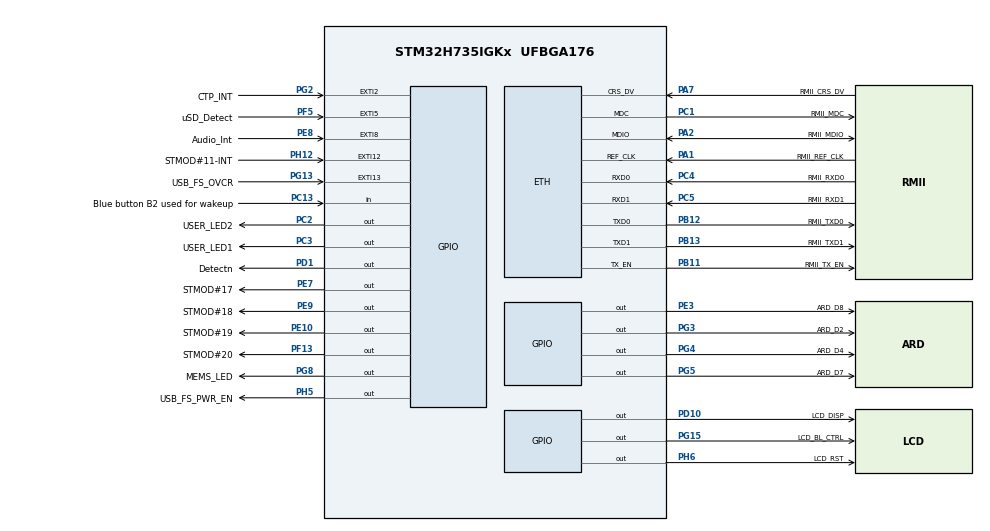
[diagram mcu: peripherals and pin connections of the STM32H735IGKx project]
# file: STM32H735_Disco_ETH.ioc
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CORTEX_M7.AccessPermission_S-Cortex_Memory_Protection_Unit_Region1_Settings_S=MPU_REGION_FULL_ACCESS
CORTEX_M7.AccessPermission_S-Cortex_Memory_Protection_Unit_Region2_Settings_S=MPU_REGION_FULL_ACCESS
CORTEX_M7.BaseAddress_S-Cortex_Memory_Protection_Unit_Region1_Settings_S=0x30000000
CORTEX_M7.BaseAddress_S-Cortex_Memory_Protection_Unit_Region2_Settings_S=0x30000000
CORTEX_M7.CPU_DCache=Enabled
CORTEX_M7.CPU_ICache=Enabled
CORTEX_M7.DisableExec_S-Cortex_Memory_Protection_Unit_Region1_Settings_S=MPU_INSTRUCTION_ACCESS_DISABLE
CORTEX_M7.DisableExec_S-Cortex_Memory_Protection_Unit_Region2_Settings_S=MPU_INSTRUCTION_ACCESS_DISABLE
CORTEX_M7.Enable_S-Cortex_Memory_Protection_Unit_Region1_Settings_S=MPU_REGION_ENABLE
CORTEX_M7.Enable_S-Cortex_Memory_Protection_Unit_Region2_Settings_S=MPU_REGION_ENABLE
CORTEX_M7.IsBufferable_S-Cortex_Memory_Protection_Unit_Region2_Settings_S=MPU_ACCESS_BUFFERABLE
CORTEX_M7.IsShareable_S-Cortex_Memory_Protection_Unit_Region2_Settings_S=MPU_ACCESS_SHAREABLE
CORTEX_M7.Size_S-Cortex_Memory_Protection_Unit_Region1_Settings_S=MPU_REGION_SIZE_32KB
CORTEX_M7.Size_S-Cortex_Memory_Protection_Unit_Region2_Settings_S=MPU_REGION_SIZE_512B
CORTEX_M7.TypeExtField_S-Cortex_Memory_Protection_Unit_Region1_Settings_S=MPU_TEX_LEVEL1
CORTEX_M7.default_mode_Activation=1
ETH.MediaInterface=HAL_ETH_RMII_MODE
ETH.RxBuffAddress=0x30000200
ETH.RxBuffLen=1536
ETH.TxDescAddress=0x30000100
FREERTOS.Tasks01=defaultTask,24,512,StartDefaultTask,Default,NULL,Dynamic,NULL,NULL
FREERTOS.configCHECK_FOR_STACK_OVERFLOW=1
FREERTOS.configMINIMAL_STACK_SIZE=512
FREERTOS.configTOTAL_HEAP_SIZE=30*1024
FREERTOS.configUSE_NEWLIB_REENTRANT=1
LWIP.BSP.number=1
LWIP.IP_ADDRESS=192.168.001.010
LWIP.LWIP_DHCP=0
LWIP.LWIP_RAM_HEAP_POINTER=0x30000200
LWIP.MEM_SIZE=32232
LWIP.NETMASK_ADDRESS=255.255.255.000
LWIP.TCP_MSS=1460
LWIP.TCP_SND_BUF=5840
LWIP.TCP_SND_QUEUELEN=16
LWIP.Version=v2.1.2_Cube
LWIP0.BSP.STBoard=false
LWIP0.BSP.api=BSP_COMPONENT_DRIVER
LWIP0.BSP.component=LAN8742
LWIP0.BSP.i2caddr=0
LWIP0.BSP.instance=LAN8742
LWIP0.BSP.name=Driver_PHY
LWIP0.BSP.semaphore=S_LAN8742
LWIP0.BSP.solution=LAN8742
Mcu.Family=STM32H7
Mcu.Name=STM32H735IGKx
Mcu.Package=UFBGA176
NVIC.ETH_IRQn=true\:5\:0\:false\:false\:true\:true\:true\:true\:true
NVIC.PriorityGroup=NVIC_PRIORITYGROUP_4
NVIC.TIM6_DAC_IRQn=true\:15\:0\:false\:false\:true\:false\:false\:true\:true
NVIC.TimeBase=TIM6_DAC_IRQn
NVIC.TimeBaseIP=TIM6
PA0.GPIO_Label=ARD_D3
PA0.Signal=S_TIM5_CH1
PA0_C.GPIO_Label=ARD_A2
PA0_C.Signal=ADCx_INP0
PA1.GPIO_Label=RMII_REF_CLK
PA1.GPIO_Speed=GPIO_SPEED_FREQ_VERY_HIGH
PA1.Mode=RMII
PA1.Signal=ETH_REF_CLK
PA10.GPIO_Label=USB_FS_ID
PA10.Signal=USB_OTG_HS_ID
PA11.GPIO_Label=USB_FS_DM
PA11.Signal=USB_OTG_HS_DM
PA12.GPIO_Label=USB_FS_DP
PA12.Signal=USB_OTG_HS_DP
PA13(JTMS/SWDIO).GPIO_Label=JTMS
PA13(JTMS/SWDIO).Signal=DEBUG_JTMS-SWDIO
PA14(JTCK/SWCLK).GPIO_Label=JTCK
PA14(JTCK/SWCLK).Signal=DEBUG_JTCK-SWCLK
PA15(JTDI).GPIO_Label=JTDI
PA15(JTDI).Signal=DEBUG_JTDI
PA1_C.GPIO_Label=ARD_A3
PA1_C.Signal=ADCx_INP1
PA2.GPIO_Label=RMII_MDIO
PA2.GPIO_Speed=GPIO_SPEED_FREQ_VERY_HIGH
PA2.Mode=RMII
PA2.Signal=ETH_MDIO
PA3.GPIO_Label=LCD_B5
PA3.GPIO_Speed=GPIO_SPEED_FREQ_LOW
PA3.Signal=LTDC_B5
PA4.GPIO_Label=LCD_VSYNC
PA4.GPIO_Speed=GPIO_SPEED_FREQ_LOW
PA4.Signal=LTDC_VSYNC
PA5.GPIO_Label=DAC1_OUT2
PA5.Signal=COMP_DAC12_group
PA6.GPIO_Label=LCD_G2
PA6.GPIO_Speed=GPIO_SPEED_FREQ_LOW
PA6.Signal=LTDC_G2
PA7.GPIO_Label=RMII_CRS_DV
PA7.GPIO_Speed=GPIO_SPEED_FREQ_VERY_HIGH
PA7.Mode=RMII
PA7.Signal=ETH_CRS_DV
PA8.GPIO_Label=LCD_B3
PA8.GPIO_Speed=GPIO_SPEED_FREQ_LOW
PA8.Signal=LTDC_B3
PA9.GPIO_Label=USB_FS_VBUS
PA9.Signal=USB_OTG_HS_VBUS
PB0.GPIO_Label=LCD_G1
PB0.GPIO_Speed=GPIO_SPEED_FREQ_LOW
PB0.Signal=LTDC_G1
PB1.GPIO_Label=LCD_G0
PB1.GPIO_Speed=GPIO_SPEED_FREQ_LOW
PB1.Signal=LTDC_G0
PB10.GPIO_Label=RMII_RX_ER
PB10.Signal=ETH_RX_ER
PB11.GPIO_Label=RMII_TX_EN
PB11.GPIO_Speed=GPIO_SPEED_FREQ_VERY_HIGH
PB11.Mode=RMII
PB11.Signal=ETH_TX_EN
PB12.GPIO_Label=RMII_TXD0
PB12.GPIO_Speed=GPIO_SPEED_FREQ_VERY_HIGH
PB12.Mode=RMII
PB12.Signal=ETH_TXD0
PB13.GPIO_Label=RMII_TXD1
PB13.GPIO_Speed=GPIO_SPEED_FREQ_VERY_HIGH
PB13.Mode=RMII
PB13.Signal=ETH_TXD1
PB14.GPIO_Label=ARD_D1
PB14.GPIO_PuPd=GPIO_NOPULL
PB14.Signal=USART1_TX
PB15.GPIO_Label=ARD_D0
PB15.GPIO_PuPd=GPIO_NOPULL
PB15.Signal=USART1_RX
PB2.GPIO_Label=OCSPI1_DQS
PB2.Signal=OCTOSPIM_P1_DQS
PB3(JTDO/TRACESWO).GPIO_Label=JTDO
PB3(JTDO/TRACESWO).Signal=DEBUG_JTDO-SWO
PB4(NJTRST).GPIO_Label=NJTRST
PB4(NJTRST).Signal=DEBUG_JTRST
PB5.GPIO_Label=FDCAN2_RX
PB5.Signal=FDCAN2_RX
PB6.GPIO_Label=FDCAN2_TX
PB6.Signal=FDCAN2_TX
PB7.GPIO_Label=ARD_D9
PB7.Signal=S_TIM4_CH2
PB8.GPIO_Label=LCD_B6
PB8.GPIO_Speed=GPIO_SPEED_FREQ_LOW
PB8.Signal=LTDC_B6
PB9.GPIO_Label=LCD_B7
PB9.GPIO_Speed=GPIO_SPEED_FREQ_LOW
PB9.Signal=LTDC_B7
PC0.GPIO_Label=ARD_A0
PC0.Signal=ADCx_INP10
PC1.GPIO_Label=RMII_MDC
PC1.GPIO_Speed=GPIO_SPEED_FREQ_VERY_HIGH
PC1.Mode=RMII
PC1.Signal=ETH_MDC
PC10.GPIO_Label=SDIO1_D2
PC10.Signal=SDMMC1_D2
PC11.GPIO_Label=SDIO1_D3
PC11.Signal=SDMMC1_D3
PC12.GPIO_Label=SDIO1_CK
PC12.Signal=SDMMC1_CK
PC13.GPIO_Label=Blue button B2 used for wakeup
PC13.Signal=GPIO_Input
PC2.GPIO_Label=USER_LED2
PC2.Signal=GPIO_Output
PC2_C.GPIO_Label=ARD_A4
PC2_C.Signal=ADC3_INP0
PC3.GPIO_Label=USER_LED1
PC3.Signal=GPIO_Output
PC3_C.GPIO_Label=ARD_A5
PC3_C.Signal=ADC3_INP1
PC4.GPIO_Label=RMII_RXD0
PC4.GPIO_Speed=GPIO_SPEED_FREQ_VERY_HIGH
PC4.Mode=RMII
PC4.Signal=ETH_RXD0
PC5.GPIO_Label=RMII_RXD1
PC5.GPIO_Speed=GPIO_SPEED_FREQ_VERY_HIGH
PC5.Mode=RMII
PC5.Signal=ETH_RXD1
PC6.GPIO_Label=LCD_HSYNC
PC6.GPIO_Speed=GPIO_SPEED_FREQ_LOW
PC6.Signal=LTDC_HSYNC
PC7.GPIO_Label=LCD_G6
PC7.GPIO_Speed=GPIO_SPEED_FREQ_LOW
PC7.Signal=LTDC_G6
PC8.GPIO_Label=SDIO1_D0
PC8.Signal=SDMMC1_D0
PC9.GPIO_Label=SDIO1_D1
PC9.Signal=SDMMC1_D1
PD0.GPIO_Label=LCD_B1
PD0.GPIO_Speed=GPIO_SPEED_FREQ_LOW
PD0.Signal=LTDC_B1
PD1.GPIO_Label=Detectn
PD1.GPIO_PuPd=GPIO_NOPULL
PD1.Signal=GPIO_Output
PD10.GPIO_Label=LCD_DISP
PD10.GPIO_Speed=GPIO_SPEED_FREQ_LOW
PD10.Signal=GPIO_Output
PD11.GPIO_Label=OCSPI1_IO0
PD11.Signal=OCTOSPIM_P1_IO0
PD12.GPIO_Label=OCSPI1_IO1
PD12.Signal=OCTOSPIM_P1_IO1
PD13.GPIO_Label=OCSPI1_IO3
PD13.Signal=OCTOSPIM_P1_IO3
PD14.GPIO_Label=STMOD\#14-PWM
PD14.Signal=S_TIM4_CH3
PD15.GPIO_Label=ARD_D6
PD15.Signal=S_TIM4_CH4
PD2.GPIO_Label=SDIO1_CMD
PD2.Signal=SDMMC1_CMD
PD3.GPIO_Label=LCD_G7
PD3.GPIO_Speed=GPIO_SPEED_FREQ_LOW
PD3.Signal=LTDC_G7
PD4.GPIO_Label=OCSPI1_IO4
PD4.Signal=OCTOSPIM_P1_IO4
PD5.GPIO_Label=OCSPI1_IO5
PD5.Signal=OCTOSPIM_P1_IO5
PD6.GPIO_Label=LCD_B2
PD6.GPIO_Speed=GPIO_SPEED_FREQ_LOW
PD6.Signal=LTDC_B2
PD7.GPIO_Label=OCSPI1_IO7
PD7.Signal=OCTOSPIM_P1_IO7
PD8.GPIO_Label=T_VCP_TX
PD8.GPIO_PuPd=GPIO_NOPULL
PD8.Signal=USART3_TX
PD9.GPIO_Label=T_VCP_RX
PD9.GPIO_PuPd=GPIO_NOPULL
PD9.Signal=USART3_RX
PE0.GPIO_Label=LCD_R0
PE0.GPIO_Speed=GPIO_SPEED_FREQ_LOW
PE0.Signal=LTDC_R0
PE1.GPIO_Label=LCD_R6
PE1.GPIO_Speed=GPIO_SPEED_FREQ_LOW
PE1.Signal=LTDC_R6
PE10.GPIO_Label=STMOD\#19
PE10.Signal=GPIO_Output
PE11.GPIO_Label=LCD_G3
PE11.GPIO_Speed=GPIO_SPEED_FREQ_LOW
PE11.Signal=LTDC_G3
PE12.GPIO_Label=LCD_B4
PE12.GPIO_Speed=GPIO_SPEED_FREQ_LOW
PE12.Signal=LTDC_B4
PE13.GPIO_Label=LCD_DE
PE13.GPIO_Speed=GPIO_SPEED_FREQ_LOW
PE13.Signal=LTDC_DE
PE14.GPIO_Label=ARD_D5
PE14.Signal=S_TIM1_CH4
PE15.GPIO_Label=LCD_R7
PE15.GPIO_Speed=GPIO_SPEED_FREQ_LOW
PE15.Signal=LTDC_R7
PE2.GPIO_Label=OCSPI1_IO2
PE2.Signal=OCTOSPIM_P1_IO2
PE3.GPIO_Label=ARD_D8
PE3.Signal=GPIO_Output
PE4.GPIO_Label=SAI4_D2
PE4.Signal=SAI4_D2
PE5.GPIO_Label=SAI4_CK2
PE5.Signal=SAI4_CK2
PE6.GPIO_Label=SAI1_SD_A
PE6.Signal=SAI1_SD_A
PE7.GPIO_Label=STMOD\#17
PE7.Signal=GPIO_Output
PE8.GPIO_Label=Audio_Int
PE8.Signal=GPXTI8
PE9.GPIO_Label=STMOD\#18
PE9.Signal=GPIO_Output
PF0.GPIO_Label=OCSPI2_IO0
PF0.Signal=OCTOSPIM_P2_IO0
PF1.GPIO_Label=OCSPI2_IO1
PF1.Signal=OCTOSPIM_P2_IO1
PF10.GPIO_Label=OCSPI1_CLK
PF10.Signal=OCTOSPIM_P1_CLK
PF11.GPIO_Label=SPI5_MOSI
PF11.Signal=SPI5_MOSI
PF12.GPIO_Label=OCSPI2_DQS
PF12.Signal=OCTOSPIM_P2_DQS
PF13.GPIO_Label=STMOD\#20
PF13.Signal=GPIO_Output
PF14.GPIO_Label=I2C4_SCL
PF14.Signal=I2C4_SCL
PF15.GPIO_Label=I2C4_SDA
PF15.Signal=I2C4_SDA
PF2.GPIO_Label=OCSPI2_IO2
PF2.Signal=OCTOSPIM_P2_IO2
PF3.GPIO_Label=OCSPI2_IO3
PF3.Signal=OCTOSPIM_P2_IO3
PF4.GPIO_Label=OCSPI2_CLK
PF4.Signal=OCTOSPIM_P2_CLK
PF5.GPIO_Label=uSD_Detect
PF5.Signal=GPXTI5
PF6.GPIO_Label=SAI1_SD_B
PF6.Signal=SAI1_SD_B
PF7.GPIO_Label=SAI1_MCLK_B
PF7.Signal=SAI1_MCLK_B
PF8.GPIO_Label=SAI1_SCK_B
PF8.Signal=SAI1_SCK_B
PF9.GPIO_Label=SAI1_FS_B
PF9.Signal=SAI1_FS_B
PG0.GPIO_Label=OCSPI2_IO4
PG0.Signal=OCTOSPIM_P2_IO4
PG1.GPIO_Label=OCSPI2_IO5
PG1.Signal=OCTOSPIM_P2_IO5
PG10.GPIO_Label=OCSPI2_IO6
PG10.Signal=OCTOSPIM_P2_IO6
PG11.GPIO_Label=OCSPI2_IO7
PG11.Signal=OCTOSPIM_P2_IO7
PG12.GPIO_Label=OCSPI2_NCS
PG12.Signal=OCTOSPIM_P2_NCS
PG13.GPIO_Label=USB_FS_OVCR
PG13.Signal=GPXTI13
PG14.GPIO_Label=LCD_B0
PG14.GPIO_Speed=GPIO_SPEED_FREQ_LOW
PG14.Signal=LTDC_B0
PG15.GPIO_Label=LCD_BL_CTRL
PG15.GPIO_Speed=GPIO_SPEED_FREQ_LOW
PG15.Signal=GPIO_Output
PG2.GPIO_Label=CTP_INT
PG2.Signal=GPXTI2
PG3.GPIO_Label=ARD_D2
PG3.Signal=GPIO_Output
PG4.GPIO_Label=ARD_D4
PG4.Signal=GPIO_Output
PG5.GPIO_Label=ARD_D7
PG5.Signal=GPIO_Output
PG6.GPIO_Label=OCSPI1_NCS
PG6.Signal=OCTOSPIM_P1_NCS
PG7.GPIO_Label=LCD_CLK
PG7.GPIO_Speed=GPIO_SPEED_FREQ_LOW
PG7.Signal=LTDC_CLK
PG8.GPIO_Label=MEMS_LED
PG8.Signal=GPIO_Output
PG9.GPIO_Label=OCSPI1_IO6
PG9.Signal=OCTOSPIM_P1_IO6
PH10.GPIO_Label=LCD_R4
PH10.GPIO_Speed=GPIO_SPEED_FREQ_LOW
PH10.Signal=LTDC_R4
PH11.GPIO_Label=LCD_R5
PH11.GPIO_Speed=GPIO_SPEED_FREQ_LOW
PH11.Signal=LTDC_R5
PH12.GPIO_Label=STMOD\#11-INT
PH12.Signal=GPXTI12
PH13.GPIO_Label=FDCAN1_TX
PH13.Signal=FDCAN1_TX
PH14.GPIO_Label=FDCAN1_RX
PH14.Signal=FDCAN1_RX
PH15.GPIO_Label=LCD_G4
PH15.GPIO_Speed=GPIO_SPEED_FREQ_LOW
PH15.Signal=LTDC_G4
PH2.GPIO_Label=ARD_A1
PH2.Signal=ADC3_INP13
PH3.GPIO_Label=LCD_R1
PH3.GPIO_Speed=GPIO_SPEED_FREQ_LOW
PH3.Signal=LTDC_R1
PH4.GPIO_Label=LCD_G5
PH4.GPIO_Speed=GPIO_SPEED_FREQ_LOW
PH4.Signal=LTDC_G5
PH5.GPIO_Label=USB_FS_PWR_EN
PH5.Signal=GPIO_Output
PH6.GPIO_Label=LCD_RST
PH6.GPIO_Speed=GPIO_SPEED_FREQ_LOW
PH6.Signal=GPIO_Output
PH7.GPIO_Label=SPI5_MISO
PH7.Signal=SPI5_MISO
PH8.GPIO_Label=LCD_R2
PH8.GPIO_Speed=GPIO_SPEED_FREQ_LOW
PH8.Signal=LTDC_R2
PH9.GPIO_Label=LCD_R3
PH9.GPIO_Speed=GPIO_SPEED_FREQ_LOW
PH9.Signal=LTDC_R3
ProjectManager.HeapSize=0x200
ProjectManager.StackSize=0x400
ProjectManager.TargetToolchain=STM32CubeIDE
RCC.ADCFreq_Value=204800000
RCC.APB1Freq_Value=125000000
RCC.APB2Freq_Value=125000000
RCC.APB3Freq_Value=125000000
RCC.APB4Freq_Value=125000000
RCC.CortexFreq_Value=500000000
RCC.D1PPRE=RCC_APB3_DIV2
RCC.D2PPRE1=RCC_APB1_DIV2
RCC.D2PPRE2=RCC_APB2_DIV2
RCC.D3PPRE=RCC_APB4_DIV2
RCC.DIVM1=16
RCC.DIVM2=5
RCC.DIVN1=125
RCC.DIVN2=80
RCC.DIVP1=1
RCC.DIVP2=5
RCC.DIVQ1=4
RCC.HCLKFreq_Value=250000000
RCC.HPRE=RCC_HCLK_DIV2
RCC.PLL2FRACN=0
RCC.PLL3FRACN=0
RCC.PLLFRACN=0
RCC.SYSCLKFreq_VALUE=500000000
RCC.SYSCLKSource=RCC_SYSCLKSOURCE_PLLCLK
RCC.USBCLockSelection=RCC_USBCLKSOURCE_HSI48
RCC.USBFreq_Value=48000000
SH.ADCx_INP0.0=ADC1_INP0
SH.ADCx_INP0.1=ADC2_INP0
SH.ADCx_INP1.0=ADC2_INP1
SH.ADCx_INP1.1=ADC1_INP1
SH.ADCx_INP10.0=ADC1_INP10
SH.COMP_DAC12_group.0=DAC1_OUT2
SH.S_TIM1_CH4.0=TIM1_CH4
SH.S_TIM4_CH2.0=TIM4_CH2
SH.S_TIM4_CH3.0=TIM4_CH3
SH.S_TIM4_CH4.0=TIM4_CH4
SH.S_TIM5_CH1.0=TIM5_CH1
VP_FREERTOS_VS_CMSIS_V2.Mode=CMSIS_V2
VP_LWIP_VS_Enabled.Mode=Enabled
VP_SYS_VS_tim6.Mode=TIM6
board=STM32H735G-DK

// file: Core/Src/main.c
/* USER CODE BEGIN Header */
/**
  ******************************************************************************
  * @file           : main.c
  * @brief          : Main program body
  ******************************************************************************
  * @attention
  *
  * Copyright (c) 2022 STMicroelectronics.
  * All rights reserved.
  *
  * This software is licensed under terms that can be found in the LICENSE file
  * in the root directory of this software component.
  * If no LICENSE file comes with this software, it is provided AS-IS.
  *
  ******************************************************************************
  */
/* USER CODE END Header */
#include "main.h"
#include "cmsis_os.h"
#include "lwip.h"

/* USER CODE BEGIN Includes */
/* ETH_CODE: add lwiperf, see comment in StartDefaultTask function */
#include "lwip/apps/lwiperf.h"
/* USER CODE END Includes */

/* Definitions for defaultTask */
osThreadId_t defaultTaskHandle;
const osThreadAttr_t defaultTask_attributes = {
  .name = "defaultTask",
  .stack_size = 512 * 4,
  .priority = (osPriority_t) osPriorityNormal,
};

void SystemClock_Config(void);
static void MPU_Config(void);
static void MX_GPIO_Init(void);
void StartDefaultTask(void *argument);

int main(void)
{

  /* MPU Configuration--------------------------------------------------------*/
  MPU_Config();

  /* Enable I-Cache---------------------------------------------------------*/
  SCB_EnableICache();

  /* Enable D-Cache---------------------------------------------------------*/
  SCB_EnableDCache();

  /* MCU Configuration--------------------------------------------------------*/

  /* Reset of all peripherals, Initializes the Flash interface and the Systick. */
  HAL_Init();

  /* Configure the system clock */
  SystemClock_Config();

  /* Initialize all configured peripherals */
  MX_GPIO_Init();

  /* Init scheduler */
  osKernelInitialize();

  /* Create the thread(s) */
  /* creation of defaultTask */
  defaultTaskHandle = osThreadNew(StartDefaultTask, NULL, &defaultTask_attributes);

  /* Start scheduler */
  osKernelStart();

  /* We should never get here as control is now taken by the scheduler */
  /* Infinite loop */
  while (1)
  {

  }
}

void SystemClock_Config(void)
{
  RCC_OscInitTypeDef RCC_OscInitStruct = {0};
  RCC_ClkInitTypeDef RCC_ClkInitStruct = {0};

  /** Supply configuration update enable
  */
  HAL_PWREx_ConfigSupply(PWR_DIRECT_SMPS_SUPPLY);

  /** Configure the main internal regulator output voltage
  */
  __HAL_PWR_VOLTAGESCALING_CONFIG(PWR_REGULATOR_VOLTAGE_SCALE0);

  while(!__HAL_PWR_GET_FLAG(PWR_FLAG_VOSRDY)) {}

  /** Initializes the RCC Oscillators according to the specified parameters
  * in the RCC_OscInitTypeDef structure.
  */
  RCC_OscInitStruct.OscillatorType = RCC_OSCILLATORTYPE_HSI;
  RCC_OscInitStruct.HSIState = RCC_HSI_DIV1;
  RCC_OscInitStruct.HSICalibrationValue = RCC_HSICALIBRATION_DEFAULT;
  RCC_OscInitStruct.PLL.PLLState = RCC_PLL_ON;
  RCC_OscInitStruct.PLL.PLLSource = RCC_PLLSOURCE_HSI;
  RCC_OscInitStruct.PLL.PLLM = 16;
  RCC_OscInitStruct.PLL.PLLN = 125;
  RCC_OscInitStruct.PLL.PLLP = 1;
  RCC_OscInitStruct.PLL.PLLQ = 4;
  RCC_OscInitStruct.PLL.PLLR = 2;
  RCC_OscInitStruct.PLL.PLLRGE = RCC_PLL1VCIRANGE_2;
  RCC_OscInitStruct.PLL.PLLVCOSEL = RCC_PLL1VCOWIDE;
  RCC_OscInitStruct.PLL.PLLFRACN = 0;
  if (HAL_RCC_OscConfig(&RCC_OscInitStruct) != HAL_OK)
  {
    Error_Handler();
  }

  /** Initializes the CPU, AHB and APB buses clocks
  */
  RCC_ClkInitStruct.ClockType = RCC_CLOCKTYPE_HCLK|RCC_CLOCKTYPE_SYSCLK
                              |RCC_CLOCKTYPE_PCLK1|RCC_CLOCKTYPE_PCLK2
                              |RCC_CLOCKTYPE_D3PCLK1|RCC_CLOCKTYPE_D1PCLK1;
  RCC_ClkInitStruct.SYSCLKSource = RCC_SYSCLKSOURCE_PLLCLK;
  RCC_ClkInitStruct.SYSCLKDivider = RCC_SYSCLK_DIV1;
  RCC_ClkInitStruct.AHBCLKDivider = RCC_HCLK_DIV2;
  RCC_ClkInitStruct.APB3CLKDivider = RCC_APB3_DIV2;
  RCC_ClkInitStruct.APB1CLKDivider = RCC_APB1_DIV2;
  RCC_ClkInitStruct.APB2CLKDivider = RCC_APB2_DIV2;
  RCC_ClkInitStruct.APB4CLKDivider = RCC_APB4_DIV2;

  if (HAL_RCC_ClockConfig(&RCC_ClkInitStruct, FLASH_LATENCY_3) != HAL_OK)
  {
    Error_Handler();
  }
}

static void MX_GPIO_Init(void)
{
  GPIO_InitTypeDef GPIO_InitStruct = {0};

  /* GPIO Ports Clock Enable */
  __HAL_RCC_GPIOB_CLK_ENABLE();
  __HAL_RCC_GPIOG_CLK_ENABLE();
  __HAL_RCC_GPIOD_CLK_ENABLE();
  __HAL_RCC_GPIOA_CLK_ENABLE();
  __HAL_RCC_GPIOE_CLK_ENABLE();
  __HAL_RCC_GPIOC_CLK_ENABLE();
  __HAL_RCC_GPIOH_CLK_ENABLE();
  __HAL_RCC_GPIOF_CLK_ENABLE();

  /*Configure GPIO pin Output Level */
  HAL_GPIO_WritePin(GPIOD, Detectn_Pin|LCD_DISP_Pin, GPIO_PIN_RESET);

  /*Configure GPIO pin Output Level */
  HAL_GPIO_WritePin(GPIOE, ARD_D8_Pin|STMOD_17_Pin|STMOD_19_Pin|STMOD_18_Pin, GPIO_PIN_RESET);

  /*Configure GPIO pin Output Level */
  HAL_GPIO_WritePin(GPIOG, LCD_BL_CTRL_Pin|ARD_D7_Pin|MEMS_LED_Pin|ARD_D4_Pin
                          |ARD_D2_Pin, GPIO_PIN_RESET);

  /*Configure GPIO pin Output Level */
  HAL_GPIO_WritePin(GPIOC, USER_LED2_Pin|USER_LED1_Pin, GPIO_PIN_RESET);

  /*Configure GPIO pin Output Level */
  HAL_GPIO_WritePin(STMOD_20_GPIO_Port, STMOD_20_Pin, GPIO_PIN_RESET);

  /*Configure GPIO pin Output Level */
  HAL_GPIO_WritePin(GPIOH, LCD_RST_Pin|USB_FS_PWR_EN_Pin, GPIO_PIN_RESET);

  /*Configure GPIO pins : LCD_B6_Pin LCD_B7_Pin LCD_G0_Pin LCD_G1_Pin */
  GPIO_InitStruct.Pin = LCD_B6_Pin|LCD_B7_Pin|LCD_G0_Pin|LCD_G1_Pin;
  GPIO_InitStruct.Mode = GPIO_MODE_AF_PP;
  GPIO_InitStruct.Pull = GPIO_NOPULL;
  GPIO_InitStruct.Speed = GPIO_SPEED_FREQ_LOW;
  GPIO_InitStruct.Alternate = GPIO_AF14_LTDC;
  HAL_GPIO_Init(GPIOB, &GPIO_InitStruct);

  /*Configure GPIO pins : FDCAN2_TX_Pin FDCAN2_RX_Pin */
  GPIO_InitStruct.Pin = FDCAN2_TX_Pin|FDCAN2_RX_Pin;
  GPIO_InitStruct.Mode = GPIO_MODE_AF_PP;
  GPIO_InitStruct.Pull = GPIO_NOPULL;
  GPIO_InitStruct.Speed = GPIO_SPEED_FREQ_LOW;
  GPIO_InitStruct.Alternate = GPIO_AF9_FDCAN2;
  HAL_GPIO_Init(GPIOB, &GPIO_InitStruct);

  /*Configure GPIO pins : OCSPI2_IO7_Pin OCSPI2_IO5_Pin OCSPI2_IO4_Pin */
  GPIO_InitStruct.Pin = OCSPI2_IO7_Pin|OCSPI2_IO5_Pin|OCSPI2_IO4_Pin;
  GPIO_InitStruct.Mode = GPIO_MODE_AF_PP;
  GPIO_InitStruct.Pull = GPIO_NOPULL;
  GPIO_InitStruct.Speed = GPIO_SPEED_FREQ_VERY_HIGH;
  GPIO_InitStruct.Alternate = GPIO_AF9_OCTOSPIM_P2;
  HAL_GPIO_Init(GPIOG, &GPIO_InitStruct);

  /*Configure GPIO pin : OCSPI1_IO6_Pin */
  GPIO_InitStruct.Pin = OCSPI1_IO6_Pin;
  GPIO_InitStruct.Mode = GPIO_MODE_AF_PP;
  GPIO_InitStruct.Pull = GPIO_NOPULL;
  GPIO_InitStruct.Speed = GPIO_SPEED_FREQ_VERY_HIGH;
  GPIO_InitStruct.Alternate = GPIO_AF9_OCTOSPIM_P1;
  HAL_GPIO_Init(OCSPI1_IO6_GPIO_Port, &GPIO_InitStruct);

  /*Configure GPIO pins : LCD_G7_Pin LCD_B1_Pin LCD_B2_Pin */
  GPIO_InitStruct.Pin = LCD_G7_Pin|LCD_B1_Pin|LCD_B2_Pin;
  GPIO_InitStruct.Mode = GPIO_MODE_AF_PP;
  GPIO_InitStruct.Pull = GPIO_NOPULL;
  GPIO_InitStruct.Speed = GPIO_SPEED_FREQ_LOW;
  GPIO_InitStruct.Alternate = GPIO_AF14_LTDC;
  HAL_GPIO_Init(GPIOD, &GPIO_InitStruct);

  /*Configure GPIO pins : Detectn_Pin LCD_DISP_Pin */
  GPIO_InitStruct.Pin = Detectn_Pin|LCD_DISP_Pin;
  GPIO_InitStruct.Mode = GPIO_MODE_OUTPUT_PP;
  GPIO_InitStruct.Pull = GPIO_NOPULL;
  GPIO_InitStruct.Speed = GPIO_SPEED_FREQ_LOW;
  HAL_GPIO_Init(GPIOD, &GPIO_InitStruct);

  /*Configure GPIO pins : SAI4_D2_Pin SAI4_CK2_Pin */
  GPIO_InitStruct.Pin = SAI4_D2_Pin|SAI4_CK2_Pin;
  GPIO_InitStruct.Mode = GPIO_MODE_AF_PP;
  GPIO_InitStruct.Pull = GPIO_NOPULL;
  GPIO_InitStruct.Speed = GPIO_SPEED_FREQ_LOW;
  GPIO_InitStruct.Alternate = GPIO_AF10_SAI4;
  HAL_GPIO_Init(GPIOE, &GPIO_InitStruct);

  /*Configure GPIO pins : ARD_D8_Pin STMOD_17_Pin STMOD_19_Pin STMOD_18_Pin */
  GPIO_InitStruct.Pin = ARD_D8_Pin|STMOD_17_Pin|STMOD_19_Pin|STMOD_18_Pin;
  GPIO_InitStruct.Mode = GPIO_MODE_OUTPUT_PP;
  GPIO_InitStruct.Pull = GPIO_NOPULL;
  GPIO_InitStruct.Speed = GPIO_SPEED_FREQ_LOW;
  HAL_GPIO_Init(GPIOE, &GPIO_InitStruct);

  /*Configure GPIO pins : LCD_R0_Pin LCD_R6_Pin LCD_B4_Pin LCD_DE_Pin
                           LCD_R7_Pin LCD_G3_Pin */
  GPIO_InitStruct.Pin = LCD_R0_Pin|LCD_R6_Pin|LCD_B4_Pin|LCD_DE_Pin
                          |LCD_R7_Pin|LCD_G3_Pin;
  GPIO_InitStruct.Mode = GPIO_MODE_AF_PP;
  GPIO_InitStruct.Pull = GPIO_NOPULL;
  GPIO_InitStruct.Speed = GPIO_SPEED_FREQ_LOW;
  GPIO_InitStruct.Alternate = GPIO_AF14_LTDC;
  HAL_GPIO_Init(GPIOE, &GPIO_InitStruct);

  /*Configure GPIO pin : ARD_D9_Pin */
  GPIO_InitStruct.Pin = ARD_D9_Pin;
  GPIO_InitStruct.Mode = GPIO_MODE_AF_PP;
  GPIO_InitStruct.Pull = GPIO_NOPULL;
  GPIO_InitStruct.Speed = GPIO_SPEED_FREQ_LOW;
  GPIO_InitStruct.Alternate = GPIO_AF2_TIM4;
  HAL_GPIO_Init(ARD_D9_GPIO_Port, &GPIO_InitStruct);

  /*Configure GPIO pins : USB_FS_OVCR_Pin CTP_INT_Pin */
  GPIO_InitStruct.Pin = USB_FS_OVCR_Pin|CTP_INT_Pin;
  GPIO_InitStruct.Mode = GPIO_MODE_IT_RISING;
  GPIO_InitStruct.Pull = GPIO_NOPULL;
  HAL_GPIO_Init(GPIOG, &GPIO_InitStruct);

  /*Configure GPIO pins : OCSPI1_IO7_Pin OCSPI1_IO5_Pin OCSPI1_IO4_Pin */
  GPIO_InitStruct.Pin = OCSPI1_IO7_Pin|OCSPI1_IO5_Pin|OCSPI1_IO4_Pin;
  GPIO_InitStruct.Mode = GPIO_MODE_AF_PP;
  GPIO_InitStruct.Pull = GPIO_NOPULL;
  GPIO_InitStruct.Speed = GPIO_SPEED_FREQ_VERY_HIGH;
  GPIO_InitStruct.Alternate = GPIO_AF10_OCTOSPIM_P1;
  HAL_GPIO_Init(GPIOD, &GPIO_InitStruct);

  /*Configure GPIO pin : SDIO1_CMD_Pin */
  GPIO_InitStruct.Pin = SDIO1_CMD_Pin;
  GPIO_InitStruct.Mode = GPIO_MODE_AF_PP;
  GPIO_InitStruct.Pull = GPIO_NOPULL;
  GPIO_InitStruct.Speed = GPIO_SPEED_FREQ_VERY_HIGH;
  GPIO_InitStruct.Alternate = GPIO_AF12_SDMMC1;
  HAL_GPIO_Init(SDIO1_CMD_GPIO_Port, &GPIO_InitStruct);

  /*Configure GPIO pins : SDIO1_CK_Pin SDIO1_D3_Pin SDIO1_D2_Pin SDIO1_D0_Pin
                           SDIO1_D1_Pin */
  GPIO_InitStruct.Pin = SDIO1_CK_Pin|SDIO1_D3_Pin|SDIO1_D2_Pin|SDIO1_D0_Pin
                          |SDIO1_D1_Pin;
  GPIO_InitStruct.Mode = GPIO_MODE_AF_PP;
  GPIO_InitStruct.Pull = GPIO_NOPULL;
  GPIO_InitStruct.Speed = GPIO_SPEED_FREQ_VERY_HIGH;
  GPIO_InitStruct.Alternate = GPIO_AF12_SDMMC1;
  HAL_GPIO_Init(GPIOC, &GPIO_InitStruct);

  /*Configure GPIO pins : FDCAN1_RX_Pin FDCAN1_TX_Pin */
  GPIO_InitStruct.Pin = FDCAN1_RX_Pin|FDCAN1_TX_Pin;
  GPIO_InitStruct.Mode = GPIO_MODE_AF_PP;
  GPIO_InitStruct.Pull = GPIO_NOPULL;
  GPIO_InitStruct.Speed = GPIO_SPEED_FREQ_LOW;
  GPIO_InitStruct.Alternate = GPIO_AF9_FDCAN1;
  HAL_GPIO_Init(GPIOH, &GPIO_InitStruct);

  /*Configure GPIO pin : LCD_B3_Pin */
  GPIO_InitStruct.Pin = LCD_B3_Pin;
  GPIO_InitStruct.Mode = GPIO_MODE_AF_PP;
  GPIO_InitStruct.Pull = GPIO_NOPULL;
  GPIO_InitStruct.Speed = GPIO_SPEED_FREQ_LOW;
  GPIO_InitStruct.Alternate = GPIO_AF13_LTDC;
  HAL_GPIO_Init(LCD_B3_GPIO_Port, &GPIO_InitStruct);

  /*Configure GPIO pins : USB_FS_DP_Pin USB_FS_DM_Pin */
  GPIO_InitStruct.Pin = USB_FS_DP_Pin|USB_FS_DM_Pin;
  GPIO_InitStruct.Mode = GPIO_MODE_AF_PP;
  GPIO_InitStruct.Pull = GPIO_NOPULL;
  GPIO_InitStruct.Speed = GPIO_SPEED_FREQ_LOW;
  HAL_GPIO_Init(GPIOA, &GPIO_InitStruct);

  /*Configure GPIO pin : Blue_button_B2_used_for_wakeup_Pin */
  GPIO_InitStruct.Pin = Blue_button_B2_used_for_wakeup_Pin;
  GPIO_InitStruct.Mode = GPIO_MODE_INPUT;
  GPIO_InitStruct.Pull = GPIO_NOPULL;
  HAL_GPIO_Init(Blue_button_B2_used_for_wakeup_GPIO_Port, &GPIO_InitStruct);

  /*Configure GPIO pin : OCSPI1_IO2_Pin */
  GPIO_InitStruct.Pin = OCSPI1_IO2_Pin;
  GPIO_InitStruct.Mode = GPIO_MODE_AF_PP;
  GPIO_InitStruct.Pull = GPIO_NOPULL;
  GPIO_InitStruct.Speed = GPIO_SPEED_FREQ_VERY_HIGH;
  GPIO_InitStruct.Alternate = GPIO_AF9_OCTOSPIM_P1;
  HAL_GPIO_Init(OCSPI1_IO2_GPIO_Port, &GPIO_InitStruct);

  /*Configure GPIO pins : LCD_B0_Pin LCD_CLK_Pin */
  GPIO_InitStruct.Pin = LCD_B0_Pin|LCD_CLK_Pin;
  GPIO_InitStruct.Mode = GPIO_MODE_AF_PP;
  GPIO_InitStruct.Pull = GPIO_NOPULL;
  GPIO_InitStruct.Speed = GPIO_SPEED_FREQ_LOW;
  GPIO_InitStruct.Alternate = GPIO_AF14_LTDC;
  HAL_GPIO_Init(GPIOG, &GPIO_InitStruct);

  /*Configure GPIO pins : OCSPI2_IO6_Pin OCSPI2_NCS_Pin */
  GPIO_InitStruct.Pin = OCSPI2_IO6_Pin|OCSPI2_NCS_Pin;
  GPIO_InitStruct.Mode = GPIO_MODE_AF_PP;
  GPIO_InitStruct.Pull = GPIO_NOPULL;
  GPIO_InitStruct.Speed = GPIO_SPEED_FREQ_VERY_HIGH;
  GPIO_InitStruct.Alternate = GPIO_AF3_OCTOSPIM_P2;
  HAL_GPIO_Init(GPIOG, &GPIO_InitStruct);

  /*Configure GPIO pin : USB_FS_ID_Pin */
  GPIO_InitStruct.Pin = USB_FS_ID_Pin;
  GPIO_InitStruct.Mode = GPIO_MODE_AF_PP;
  GPIO_InitStruct.Pull = GPIO_NOPULL;
  GPIO_InitStruct.Speed = GPIO_SPEED_FREQ_LOW;
  GPIO_InitStruct.Alternate = GPIO_AF10_OTG1_HS;
  HAL_GPIO_Init(USB_FS_ID_GPIO_Port, &GPIO_InitStruct);

  /*Configure GPIO pins : LCD_BL_CTRL_Pin ARD_D7_Pin MEMS_LED_Pin ARD_D4_Pin
                           ARD_D2_Pin */
  GPIO_InitStruct.Pin = LCD_BL_CTRL_Pin|ARD_D7_Pin|MEMS_LED_Pin|ARD_D4_Pin
                          |ARD_D2_Pin;
  GPIO_InitStruct.Mode = GPIO_MODE_OUTPUT_PP;
  GPIO_InitStruct.Pull = GPIO_NOPULL;
  GPIO_InitStruct.Speed = GPIO_SPEED_FREQ_LOW;
  HAL_GPIO_Init(GPIOG, &GPIO_InitStruct);

  /*Configure GPIO pins : LCD_G4_Pin LCD_R5_Pin LCD_R3_Pin LCD_R2_Pin
                           LCD_R4_Pin LCD_R1_Pin */
  GPIO_InitStruct.Pin = LCD_G4_Pin|LCD_R5_Pin|LCD_R3_Pin|LCD_R2_Pin
                          |LCD_R4_Pin|LCD_R1_Pin;
  GPIO_InitStruct.Mode = GPIO_MODE_AF_PP;
  GPIO_InitStruct.Pull = GPIO_NOPULL;
  GPIO_InitStruct.Speed = GPIO_SPEED_FREQ_LOW;
  GPIO_InitStruct.Alternate = GPIO_AF14_LTDC;
  HAL_GPIO_Init(GPIOH, &GPIO_InitStruct);

  /*Configure GPIO pins : LCD_G6_Pin LCD_HSYNC_Pin */
  GPIO_InitStruct.Pin = LCD_G6_Pin|LCD_HSYNC_Pin;
  GPIO_InitStruct.Mode = GPIO_MODE_AF_PP;
  GPIO_InitStruct.Pull = GPIO_NOPULL;
  GPIO_InitStruct.Speed = GPIO_SPEED_FREQ_LOW;
  GPIO_InitStruct.Alternate = GPIO_AF14_LTDC;
  HAL_GPIO_Init(GPIOC, &GPIO_InitStruct);

  /*Configure GPIO pin : SAI1_SD_A_Pin */
  GPIO_InitStruct.Pin = SAI1_SD_A_Pin;
  GPIO_InitStruct.Mode = GPIO_MODE_AF_PP;
  GPIO_InitStruct.Pull = GPIO_NOPULL;
  GPIO_InitStruct.Speed = GPIO_SPEED_FREQ_LOW;
  GPIO_InitStruct.Alternate = GPIO_AF6_SAI1;
  HAL_GPIO_Init(SAI1_SD_A_GPIO_Port, &GPIO_InitStruct);

  /*Configure GPIO pins : OCSPI2_IO1_Pin OCSPI2_IO0_Pin OCSPI2_IO2_Pin OCSPI2_CLK_Pin
                           OCSPI2_IO3_Pin OCSPI2_DQS_Pin */
  GPIO_InitStruct.Pin = OCSPI2_IO1_Pin|OCSPI2_IO0_Pin|OCSPI2_IO2_Pin|OCSPI2_CLK_Pin
                          |OCSPI2_IO3_Pin|OCSPI2_DQS_Pin;
  GPIO_InitStruct.Mode = GPIO_MODE_AF_PP;
  GPIO_InitStruct.Pull = GPIO_NOPULL;
  GPIO_InitStruct.Speed = GPIO_SPEED_FREQ_VERY_HIGH;
  GPIO_InitStruct.Alternate = GPIO_AF9_OCTOSPIM_P2;
  HAL_GPIO_Init(GPIOF, &GPIO_InitStruct);

  /*Configure GPIO pin : OCSPI1_NCS_Pin */
  GPIO_InitStruct.Pin = OCSPI1_NCS_Pin;
  GPIO_InitStruct.Mode = GPIO_MODE_AF_PP;
  GPIO_InitStruct.Pull = GPIO_NOPULL;
  GPIO_InitStruct.Speed = GPIO_SPEED_FREQ_VERY_HIGH;
  GPIO_InitStruct.Alternate = GPIO_AF10_OCTOSPIM_P1;
  HAL_GPIO_Init(OCSPI1_NCS_GPIO_Port, &GPIO_InitStruct);

  /*Configure GPIO pins : SAI1_SD_B_Pin SAI1_SCK_B_Pin SAI1_MCLK_B_Pin SAI1_FS_B_Pin */
  GPIO_InitStruct.Pin = SAI1_SD_B_Pin|SAI1_SCK_B_Pin|SAI1_MCLK_B_Pin|SAI1_FS_B_Pin;
  GPIO_InitStruct.Mode = GPIO_MODE_AF_PP;
  GPIO_InitStruct.Pull = GPIO_NOPULL;
  GPIO_InitStruct.Speed = GPIO_SPEED_FREQ_LOW;
  GPIO_InitStruct.Alternate = GPIO_AF6_SAI1;
  HAL_GPIO_Init(GPIOF, &GPIO_InitStruct);

  /*Configure GPIO pin : uSD_Detect_Pin */
  GPIO_InitStruct.Pin = uSD_Detect_Pin;
  GPIO_InitStruct.Mode = GPIO_MODE_IT_RISING;
  GPIO_InitStruct.Pull = GPIO_NOPULL;
  HAL_GPIO_Init(uSD_Detect_GPIO_Port, &GPIO_InitStruct);

  /*Configure GPIO pins : STMOD_14_PWM_Pin ARD_D6_Pin */
  GPIO_InitStruct.Pin = STMOD_14_PWM_Pin|ARD_D6_Pin;
  GPIO_InitStruct.Mode = GPIO_MODE_AF_PP;
  GPIO_InitStruct.Pull = GPIO_NOPULL;
  GPIO_InitStruct.Speed = GPIO_SPEED_FREQ_LOW;
  GPIO_InitStruct.Alternate = GPIO_AF2_TIM4;
  HAL_GPIO_Init(GPIOD, &GPIO_InitStruct);

  /*Configure GPIO pins : OCSPI1_IO3_Pin OCSPI1_IO0_Pin OCSPI1_IO1_Pin */
  GPIO_InitStruct.Pin = OCSPI1_IO3_Pin|OCSPI1_IO0_Pin|OCSPI1_IO1_Pin;
  GPIO_InitStruct.Mode = GPIO_MODE_AF_PP;
  GPIO_InitStruct.Pull = GPIO_NOPULL;
  GPIO_InitStruct.Speed = GPIO_SPEED_FREQ_VERY_HIGH;
  GPIO_InitStruct.Alternate = GPIO_AF9_OCTOSPIM_P1;
  HAL_GPIO_Init(GPIOD, &GPIO_InitStruct);

  /*Configure GPIO pin : OCSPI1_CLK_Pin */
  GPIO_InitStruct.Pin = OCSPI1_CLK_Pin;
  GPIO_InitStruct.Mode = GPIO_MODE_AF_PP;
  GPIO_InitStruct.Pull = GPIO_NOPULL;
  GPIO_InitStruct.Speed = GPIO_SPEED_FREQ_VERY_HIGH;
  GPIO_InitStruct.Alternate = GPIO_AF9_OCTOSPIM_P1;
  HAL_GPIO_Init(OCSPI1_CLK_GPIO_Port, &GPIO_InitStruct);

  /*Configure GPIO pins : T_VCP_RX_Pin T_VCP_TX_Pin */
  GPIO_InitStruct.Pin = T_VCP_RX_Pin|T_VCP_TX_Pin;
  GPIO_InitStruct.Mode = GPIO_MODE_AF_PP;
  GPIO_InitStruct.Pull = GPIO_NOPULL;
  GPIO_InitStruct.Speed = GPIO_SPEED_FREQ_LOW;
  GPIO_InitStruct.Alternate = GPIO_AF7_USART3;
  HAL_GPIO_Init(GPIOD, &GPIO_InitStruct);

  /*Configure GPIO pins : ARD_D0_Pin ARD_D1_Pin */
  GPIO_InitStruct.Pin = ARD_D0_Pin|ARD_D1_Pin;
  GPIO_InitStruct.Mode = GPIO_MODE_AF_PP;
  GPIO_InitStruct.Pull = GPIO_NOPULL;
  GPIO_InitStruct.Speed = GPIO_SPEED_FREQ_LOW;
  GPIO_InitStruct.Alternate = GPIO_AF4_USART1;
  HAL_GPIO_Init(GPIOB, &GPIO_InitStruct);

  /*Configure GPIO pin : ARD_A0_Pin */
  GPIO_InitStruct.Pin = ARD_A0_Pin;
  GPIO_InitStruct.Mode = GPIO_MODE_ANALOG;
  GPIO_InitStruct.Pull = GPIO_NOPULL;
  HAL_GPIO_Init(ARD_A0_GPIO_Port, &GPIO_InitStruct);

  /*Configure GPIO pins : USER_LED2_Pin USER_LED1_Pin */
  GPIO_InitStruct.Pin = USER_LED2_Pin|USER_LED1_Pin;
  GPIO_InitStruct.Mode = GPIO_MODE_OUTPUT_PP;
  GPIO_InitStruct.Pull = GPIO_NOPULL;
  GPIO_InitStruct.Speed = GPIO_SPEED_FREQ_LOW;
  HAL_GPIO_Init(GPIOC, &GPIO_InitStruct);

  /*Configure GPIO pin : SPI5_MISO_Pin */
  GPIO_InitStruct.Pin = SPI5_MISO_Pin;
  GPIO_InitStruct.Mode = GPIO_MODE_AF_PP;
  GPIO_InitStruct.Pull = GPIO_NOPULL;
  GPIO_InitStruct.Speed = GPIO_SPEED_FREQ_LOW;
  GPIO_InitStruct.Alternate = GPIO_AF5_SPI5;
  HAL_GPIO_Init(SPI5_MISO_GPIO_Port, &GPIO_InitStruct);

  /*Configure GPIO pin : ARD_D5_Pin */
  GPIO_InitStruct.Pin = ARD_D5_Pin;
  GPIO_InitStruct.Mode = GPIO_MODE_AF_PP;
  GPIO_InitStruct.Pull = GPIO_NOPULL;
  GPIO_InitStruct.Speed = GPIO_SPEED_FREQ_LOW;
  GPIO_InitStruct.Alternate = GPIO_AF1_TIM1;
  HAL_GPIO_Init(ARD_D5_GPIO_Port, &GPIO_InitStruct);

  /*Configure GPIO pin : ARD_A1_Pin */
  GPIO_InitStruct.Pin = ARD_A1_Pin;
  GPIO_InitStruct.Mode = GPIO_MODE_ANALOG;
  GPIO_InitStruct.Pull = GPIO_NOPULL;
  HAL_GPIO_Init(ARD_A1_GPIO_Port, &GPIO_InitStruct);

  /*Configure GPIO pins : LCD_B5_Pin LCD_VSYNC_Pin LCD_G2_Pin */
  GPIO_InitStruct.Pin = LCD_B5_Pin|LCD_VSYNC_Pin|LCD_G2_Pin;
  GPIO_InitStruct.Mode = GPIO_MODE_AF_PP;
  GPIO_InitStruct.Pull = GPIO_NOPULL;
  GPIO_InitStruct.Speed = GPIO_SPEED_FREQ_LOW;
  GPIO_InitStruct.Alternate = GPIO_AF14_LTDC;
  HAL_GPIO_Init(GPIOA, &GPIO_InitStruct);

  /*Configure GPIO pin : SPI5_MOSI_Pin */
  GPIO_InitStruct.Pin = SPI5_MOSI_Pin;
  GPIO_InitStruct.Mode = GPIO_MODE_AF_PP;
  GPIO_InitStruct.Pull = GPIO_NOPULL;
  GPIO_InitStruct.Speed = GPIO_SPEED_FREQ_LOW;
  GPIO_InitStruct.Alternate = GPIO_AF5_SPI5;
  HAL_GPIO_Init(SPI5_MOSI_GPIO_Port, &GPIO_InitStruct);

  /*Configure GPIO pin : Audio_Int_Pin */
  GPIO_InitStruct.Pin = Audio_Int_Pin;
  GPIO_InitStruct.Mode = GPIO_MODE_IT_RISING;
  GPIO_InitStruct.Pull = GPIO_NOPULL;
  HAL_GPIO_Init(Audio_Int_GPIO_Port, &GPIO_InitStruct);

  /*Configure GPIO pins : I2C4_SDA_Pin I2C4_SCL_Pin */
  GPIO_InitStruct.Pin = I2C4_SDA_Pin|I2C4_SCL_Pin;
  GPIO_InitStruct.Mode = GPIO_MODE_AF_OD;
  GPIO_InitStruct.Pull = GPIO_NOPULL;
  GPIO_InitStruct.Speed = GPIO_SPEED_FREQ_LOW;
  GPIO_InitStruct.Alternate = GPIO_AF4_I2C4;
  HAL_GPIO_Init(GPIOF, &GPIO_InitStruct);

  /*Configure GPIO pin : STMOD_20_Pin */
  GPIO_InitStruct.Pin = STMOD_20_Pin;
  GPIO_InitStruct.Mode = GPIO_MODE_OUTPUT_PP;
  GPIO_InitStruct.Pull = GPIO_NOPULL;
  GPIO_InitStruct.Speed = GPIO_SPEED_FREQ_LOW;
  HAL_GPIO_Init(STMOD_20_GPIO_Port, &GPIO_InitStruct);

  /*Configure GPIO pin : STMOD_11_INT_Pin */
  GPIO_InitStruct.Pin = STMOD_11_INT_Pin;
  GPIO_InitStruct.Mode = GPIO_MODE_IT_RISING;
  GPIO_InitStruct.Pull = GPIO_NOPULL;
  HAL_GPIO_Init(STMOD_11_INT_GPIO_Port, &GPIO_InitStruct);

  /*Configure GPIO pin : ARD_D3_Pin */
  GPIO_InitStruct.Pin = ARD_D3_Pin;
  GPIO_InitStruct.Mode = GPIO_MODE_AF_PP;
  GPIO_InitStruct.Pull = GPIO_NOPULL;
  GPIO_InitStruct.Speed = GPIO_SPEED_FREQ_LOW;
  GPIO_InitStruct.Alternate = GPIO_AF2_TIM5;
  HAL_GPIO_Init(ARD_D3_GPIO_Port, &GPIO_InitStruct);

  /*Configure GPIO pin : LCD_G5_Pin */
  GPIO_InitStruct.Pin = LCD_G5_Pin;
  GPIO_InitStruct.Mode = GPIO_MODE_AF_PP;
  GPIO_InitStruct.Pull = GPIO_NOPULL;
  GPIO_InitStruct.Speed = GPIO_SPEED_FREQ_LOW;
  GPIO_InitStruct.Alternate = GPIO_AF9_LTDC;
  HAL_GPIO_Init(LCD_G5_GPIO_Port, &GPIO_InitStruct);

  /*Configure GPIO pin : DAC1_OUT2_Pin */
  GPIO_InitStruct.Pin = DAC1_OUT2_Pin;
  GPIO_InitStruct.Mode = GPIO_MODE_ANALOG;
  GPIO_InitStruct.Pull = GPIO_NOPULL;
  HAL_GPIO_Init(DAC1_OUT2_GPIO_Port, &GPIO_InitStruct);

  /*Configure GPIO pin : OCSPI1_DQS_Pin */
  GPIO_InitStruct.Pin = OCSPI1_DQS_Pin;
  GPIO_InitStruct.Mode = GPIO_MODE_AF_PP;
  GPIO_InitStruct.Pull = GPIO_NOPULL;
  GPIO_InitStruct.Speed = GPIO_SPEED_FREQ_VERY_HIGH;
  GPIO_InitStruct.Alternate = GPIO_AF10_OCTOSPIM_P1;
  HAL_GPIO_Init(OCSPI1_DQS_GPIO_Port, &GPIO_InitStruct);

  /*Configure GPIO pins : LCD_RST_Pin USB_FS_PWR_EN_Pin */
  GPIO_InitStruct.Pin = LCD_RST_Pin|USB_FS_PWR_EN_Pin;
  GPIO_InitStruct.Mode = GPIO_MODE_OUTPUT_PP;
  GPIO_InitStruct.Pull = GPIO_NOPULL;
  GPIO_InitStruct.Speed = GPIO_SPEED_FREQ_LOW;
  HAL_GPIO_Init(GPIOH, &GPIO_InitStruct);

  /*AnalogSwitch Config */
  HAL_SYSCFG_AnalogSwitchConfig(SYSCFG_SWITCH_PC2, SYSCFG_SWITCH_PC2_OPEN);

  /*AnalogSwitch Config */
  HAL_SYSCFG_AnalogSwitchConfig(SYSCFG_SWITCH_PC3, SYSCFG_SWITCH_PC3_OPEN);

  /*AnalogSwitch Config */
  HAL_SYSCFG_AnalogSwitchConfig(SYSCFG_SWITCH_PA1, SYSCFG_SWITCH_PA1_OPEN);

  /*AnalogSwitch Config */
  HAL_SYSCFG_AnalogSwitchConfig(SYSCFG_SWITCH_PA0, SYSCFG_SWITCH_PA0_OPEN);

}

void StartDefaultTask(void *argument)
{
  /* init code for LWIP */
  MX_LWIP_Init();
  /* USER CODE BEGIN 5 */
  /* ETH_CODE: Adding lwiperf to measure TCP/IP performance.
     * iperf 2.0.6 (or older?) is required for the tests. Newer iperf2 versions
     * might work without data check, but they send different headers.
     * iperf3 is not compatible at all.
     * Adding lwiperf.c file to the project is necessary.
     * The default include path should already contain
     * 'lwip/apps/lwiperf.h'
     */
  	LOCK_TCPIP_CORE();
    lwiperf_start_tcp_server_default(NULL, NULL);

    ip4_addr_t remote_addr;
    IP4_ADDR(&remote_addr, 192, 168, 1, 1);
    lwiperf_start_tcp_client_default(&remote_addr, NULL, NULL);
    UNLOCK_TCPIP_CORE();
    /* Infinite loop */
    for(;;)
    {
      osDelay(1000);
    }
  /* USER CODE END 5 */
}

/* MPU Configuration */

void MPU_Config(void)
{
  MPU_Region_InitTypeDef MPU_InitStruct = {0};

  /* Disables the MPU */
  HAL_MPU_Disable();

  /** Initializes and configures the Region and the memory to be protected
  */
  MPU_InitStruct.Enable = MPU_REGION_ENABLE;
  MPU_InitStruct.Number = MPU_REGION_NUMBER0;
  MPU_InitStruct.BaseAddress = 0x0;
  MPU_InitStruct.Size = MPU_REGION_SIZE_4GB;
  MPU_InitStruct.SubRegionDisable = 0x87;
  MPU_InitStruct.TypeExtField = MPU_TEX_LEVEL0;
  MPU_InitStruct.AccessPermission = MPU_REGION_NO_ACCESS;
  MPU_InitStruct.DisableExec = MPU_INSTRUCTION_ACCESS_DISABLE;
  MPU_InitStruct.IsShareable = MPU_ACCESS_SHAREABLE;
  MPU_InitStruct.IsCacheable = MPU_ACCESS_NOT_CACHEABLE;
  MPU_InitStruct.IsBufferable = MPU_ACCESS_NOT_BUFFERABLE;

  HAL_MPU_ConfigRegion(&MPU_InitStruct);

  /** Initializes and configures the Region and the memory to be protected
  */
  MPU_InitStruct.Number = MPU_REGION_NUMBER1;
  MPU_InitStruct.BaseAddress = 0x30000000;
  MPU_InitStruct.Size = MPU_REGION_SIZE_32KB;
  MPU_InitStruct.SubRegionDisable = 0x0;
  MPU_InitStruct.TypeExtField = MPU_TEX_LEVEL1;
  MPU_InitStruct.AccessPermission = MPU_REGION_FULL_ACCESS;
  MPU_InitStruct.IsShareable = MPU_ACCESS_NOT_SHAREABLE;

  HAL_MPU_ConfigRegion(&MPU_InitStruct);

  /** Initializes and configures the Region and the memory to be protected
  */
  MPU_InitStruct.Number = MPU_REGION_NUMBER2;
  MPU_InitStruct.Size = MPU_REGION_SIZE_512B;
  MPU_InitStruct.TypeExtField = MPU_TEX_LEVEL0;
  MPU_InitStruct.IsShareable = MPU_ACCESS_SHAREABLE;
  MPU_InitStruct.IsBufferable = MPU_ACCESS_BUFFERABLE;

  HAL_MPU_ConfigRegion(&MPU_InitStruct);
  /* Enables the MPU */
  HAL_MPU_Enable(MPU_PRIVILEGED_DEFAULT);

}

void HAL_TIM_PeriodElapsedCallback(TIM_HandleTypeDef *htim)
{
  if (htim->Instance == TIM6) {
    HAL_IncTick();
  }
}

void Error_Handler(void)
{
  __disable_irq();
  while (1)
  {
  }
}

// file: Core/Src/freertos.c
/* USER CODE BEGIN Header */
/**
  ******************************************************************************
  * File Name          : freertos.c
  * Description        : Code for freertos applications
  ******************************************************************************
  * @attention
  *
  * Copyright (c) 2022 STMicroelectronics.
  * All rights reserved.
  *
  * This software is licensed under terms that can be found in the LICENSE file
  * in the root directory of this software component.
  * If no LICENSE file comes with this software, it is provided AS-IS.
  *
  ******************************************************************************
  */
/* USER CODE END Header */

#include "FreeRTOS.h"
#include "task.h"
#include "main.h"

/* Hook prototypes */
void vApplicationStackOverflowHook(xTaskHandle xTask, signed char *pcTaskName);

/* USER CODE BEGIN 4 */
void vApplicationStackOverflowHook(xTaskHandle xTask, signed char *pcTaskName)
{
	 /* ETH_CODE: add breakpoint when stack oveflow is detected by FreeRTOS.
	    * Useful for debugging issues.
	    */
	   __BKPT(0);
}
/* USER CODE END 4 */
